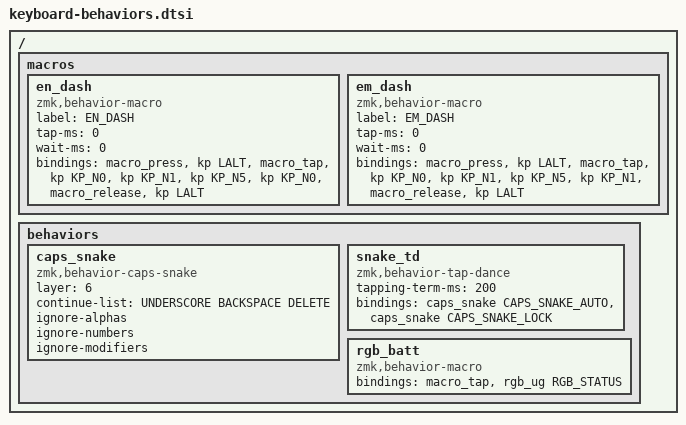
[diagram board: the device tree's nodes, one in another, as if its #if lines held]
// #define ZMK_POINTING_DEFAULT_MOVE_VAL 1500  // default: 600
#define ZMK_POINTING_DEFAULT_SCRL_VAL 20    // default: 10

#ifndef GLOVE80
#include <dt-bindings/zmk/stp.h>
#endif
#include <behaviors.dtsi>
#include <dt-bindings/zmk/backlight.h>
#include <dt-bindings/zmk/bt.h>
#include <dt-bindings/zmk/caps_snake.h>
#include <dt-bindings/zmk/keys.h>
#include <dt-bindings/zmk/pointing.h>
#include <dt-bindings/zmk/rgb.h>

/* ─── User Settings ────────────────────────────────────────────────────────
 * Override any HRM timing #define here, BEFORE the include below.
 * Example: #define HOMEY_HOLDING_TIME 300
 * ──────────────────────────────────────────────────────────────────────── */

#define DIFFICULTY_LEVEL  4 // 0:custom, 1:easy(500ms) → 5:hard(100ms)
#define HOMEY_HOLDING_TIME 200
#define HOMEY_STREAK_DECAY 200

/* ─── Home Row Mods (see hrm_behaviors.dtsi for docs) ────────────────── */
#include "hrm_behaviors.dtsi"

/ {
    macros {
        en_dash: en_dash {
            label = "EN_DASH";
            compatible = "zmk,behavior-macro";
            #binding-cells = <0>;
            tap-ms = <0>;
            wait-ms = <0>;
            bindings
                = <&macro_press &kp LALT>
                , <&macro_tap &kp KP_N0 &kp KP_N1 &kp KP_N5 &kp KP_N0>
                , <&macro_release &kp LALT>
                ;
        };

        em_dash: em_dash {
            label = "EM_DASH";
            compatible = "zmk,behavior-macro";
            #binding-cells = <0>;
            tap-ms = <0>;
            wait-ms = <0>;
            bindings
                = <&macro_press &kp LALT>
                , <&macro_tap &kp KP_N0 &kp KP_N1 &kp KP_N5 &kp KP_N1>
                , <&macro_release &kp LALT>
                ;
        };

    };
};

/ {
    behaviors {
        #include "macros.dtsi"
        #include "version.dtsi"

        caps_snake: caps_snake {
            compatible = "zmk,behavior-caps-snake";
            #binding-cells = <1>;
            layer = <6>;
            continue-list = <UNDERSCORE BACKSPACE DELETE>;
            ignore-alphas;
            ignore-numbers;
            ignore-modifiers;
        };

        snake_td: snake_td {
            compatible = "zmk,behavior-tap-dance";
            #binding-cells = <0>;
            tapping-term-ms = <200>;
            bindings = <&caps_snake CAPS_SNAKE_AUTO>, <&caps_snake CAPS_SNAKE_LOCK>;
        };

        // See README.md: Glove80 hardware adaptations.
        rgb_batt: rgb_batt {
            compatible = "zmk,behavior-macro";
            #binding-cells = <0>;
            bindings
#ifdef GLOVE80
                = <&macro_tap &rgb_ug RGB_STATUS>
                ;
#else
                = <&macro_tap &rgb_ug RGB_ON>
                , <&macro_press &stp STP_BAT>
                , <&macro_pause_for_release>
                , <&macro_release &stp STP_BAT>
                , <&macro_tap &rgb_ug RGB_OFF>
                ;
#endif
        };
    };
};
